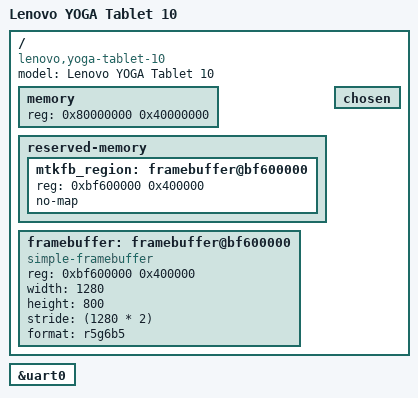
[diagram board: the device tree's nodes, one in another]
// SPDX-License-Identifier: GPL-2.0+
/*
 * Copyright (c) 2025 akku
 * Author: akku <akkun11.open@gmail.com>
 *
 */

/dts-v1/;
#include <mt6589.dtsi>
#include "mt6589-uboot.dtsi"

/ {
	model = "Lenovo YOGA Tablet 10";
	compatible = "lenovo,yoga-tablet-10", "mediatek,mt6589";

	memory {
		#address-cells = <1>;
		#size-cells = <1>;
		device_type = "memory";
		reg = <0x80000000 0x40000000>;
	};

	reserved-memory {
		#address-cells = <1>;
		#size-cells = <1>;
		ranges;

		mtkfb_region: framebuffer@bf600000{
			reg = <0xbf600000 0x400000>;
			no-map;
		};
	};

	chosen {
		#address-cells = <1>;
		#size-cells = <1>;
		ranges;
	};

	framebuffer: framebuffer@bf600000 {
		compatible = "simple-framebuffer";
		reg = <0xbf600000 0x400000>;
		width = <1280>;
		height = <800>;
		stride = <(1280 * 2)>;
		format = "r5g6b5";
		status = "okay";
	};
};

&uart0 {
	status = "okay";
};
